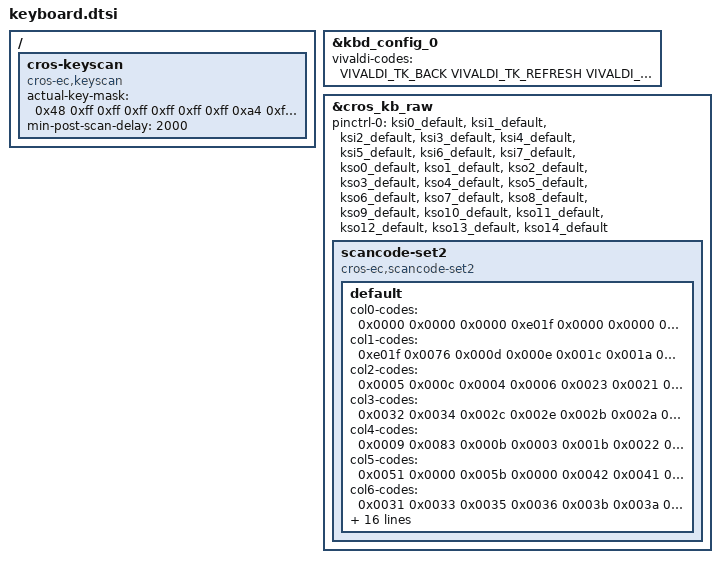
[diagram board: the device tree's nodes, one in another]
/* Copyright 2023 The ChromiumOS Authors
 * Use of this source code is governed by a BSD-style license that can be
 * found in the LICENSE file.
 */

/ {
	cros-keyscan {
		compatible = "cros-ec,keyscan";
		actual-key-mask = <
			0x48  /* C0 */
			0xff  /* C1 */
			0xff  /* C2 */
			0xff  /* C3 */
			0xff  /* C4 */
			0xff  /* C5 */
			0xff  /* C6 */
			0xa4  /* C7 */
			0xff  /* C8 */
			0xff  /* C9 */
			0x55  /* C10 */
			0xfb  /* C11 */
			0xca  /* C12 */
			0x40  /* C13 */
			0x0a  /* C13 */
		>;
		min-post-scan-delay = <2000>;
	};
};

&kbd_config_0 {
       vivaldi-codes = <
	       VIVALDI_TK_BACK              /* T1 */
	       VIVALDI_TK_REFRESH           /* T2 */
	       VIVALDI_TK_FULLSCREEN        /* T3 */
	       VIVALDI_TK_OVERVIEW          /* T4 */
	       VIVALDI_TK_SNAPSHOT          /* T5 */
	       VIVALDI_TK_BRIGHTNESS_DOWN   /* T6 */
	       VIVALDI_TK_BRIGHTNESS_UP     /* T7 */
	       VIVALDI_TK_VOL_MUTE          /* T8 */
	       VIVALDI_TK_VOL_DOWN          /* T9 */
	       VIVALDI_TK_VOL_UP            /* T10 */
	       VIVALDI_TK_MICMUTE           /* T11 */
	       VIVALDI_TK_MENU              /* T12 */
	       VIVALDI_TK_PREV_TRACK        /* T13 */
	       VIVALDI_TK_PLAY_PAUSE        /* T14 */
	       VIVALDI_TK_NEXT_TRACK        /* T15 */
       >;
};

&cros_kb_raw {
	status = "okay";
	/* No KSO2 (it's inverted and implemented by GPIO) */
	pinctrl-0 = <&ksi0_default
		     &ksi1_default
		     &ksi2_default
		     &ksi3_default
		     &ksi4_default
		     &ksi5_default
		     &ksi6_default
		     &ksi7_default
		     &kso0_default
		     &kso1_default
		     &kso2_default
		     &kso3_default
		     &kso4_default
		     &kso5_default
		     &kso6_default
		     &kso7_default
		     &kso8_default
		     &kso9_default
		     &kso10_default
		     &kso11_default
		     &kso12_default
		     &kso13_default
		     &kso14_default
	>;
	pinctrl-names = "default";

	scancode-set2 {
		compatible = "cros-ec,scancode-set2";

		default {
			col0-codes  = <0x0000 0x0000 0x0000 0xe01f 0x0000 0x0000 0xe01f 0x0000>;
			col1-codes  = <0xe01f 0x0076 0x000d 0x000e 0x001c 0x001a 0x0016 0x0015>;
			col2-codes  = <0x0005 0x000c 0x0004 0x0006 0x0023 0x0021 0x0026 0x0024>;
			col3-codes  = <0x0032 0x0034 0x002c 0x002e 0x002b 0x002a 0x0025 0x002d>;
			col4-codes  = <0x0009 0x0083 0x000b 0x0003 0x001b 0x0022 0x001e 0x001d>;
			col5-codes  = <0x0051 0x0000 0x005b 0x0000 0x0042 0x0041 0x003e 0x0043>;
			col6-codes  = <0x0031 0x0033 0x0035 0x0036 0x003b 0x003a 0x003d 0x003c>;
			col7-codes  = <0x0000 0x0000 0x0061 0x0000 0x0000 0x0012 0x0000 0x0059>;
			col8-codes  = <0x0055 0x0052 0x0054 0x004e 0x004c 0x004a 0x0045 0x004d>;
			col9-codes  = <0x0000 0x0001 0x000a 0x002f 0x004b 0x0049 0x0046 0x0044>;
			col10-codes = <0xe011 0x0000 0x006a 0x0000 0xe01f 0x0000 0x005d 0x0000>;
			col11-codes = <0x0000 0x0066 0x0000 0x005d 0x005a 0x0029 0xe072 0xe075>;
			col12-codes = <0x0000 0x0064 0x0000 0x0067 0x0000 0x0000 0xe074 0xe06b>;
			col13-codes = <0x0000 0x0000 0x0000 0x0000 0x0000 0x0000 0x0011 0x0000>;
			col14-codes = <0x0000 0x0014 0x0000 0xe014 0x0000 0x0000 0x0000 0x0000>;
		};
	};
};
